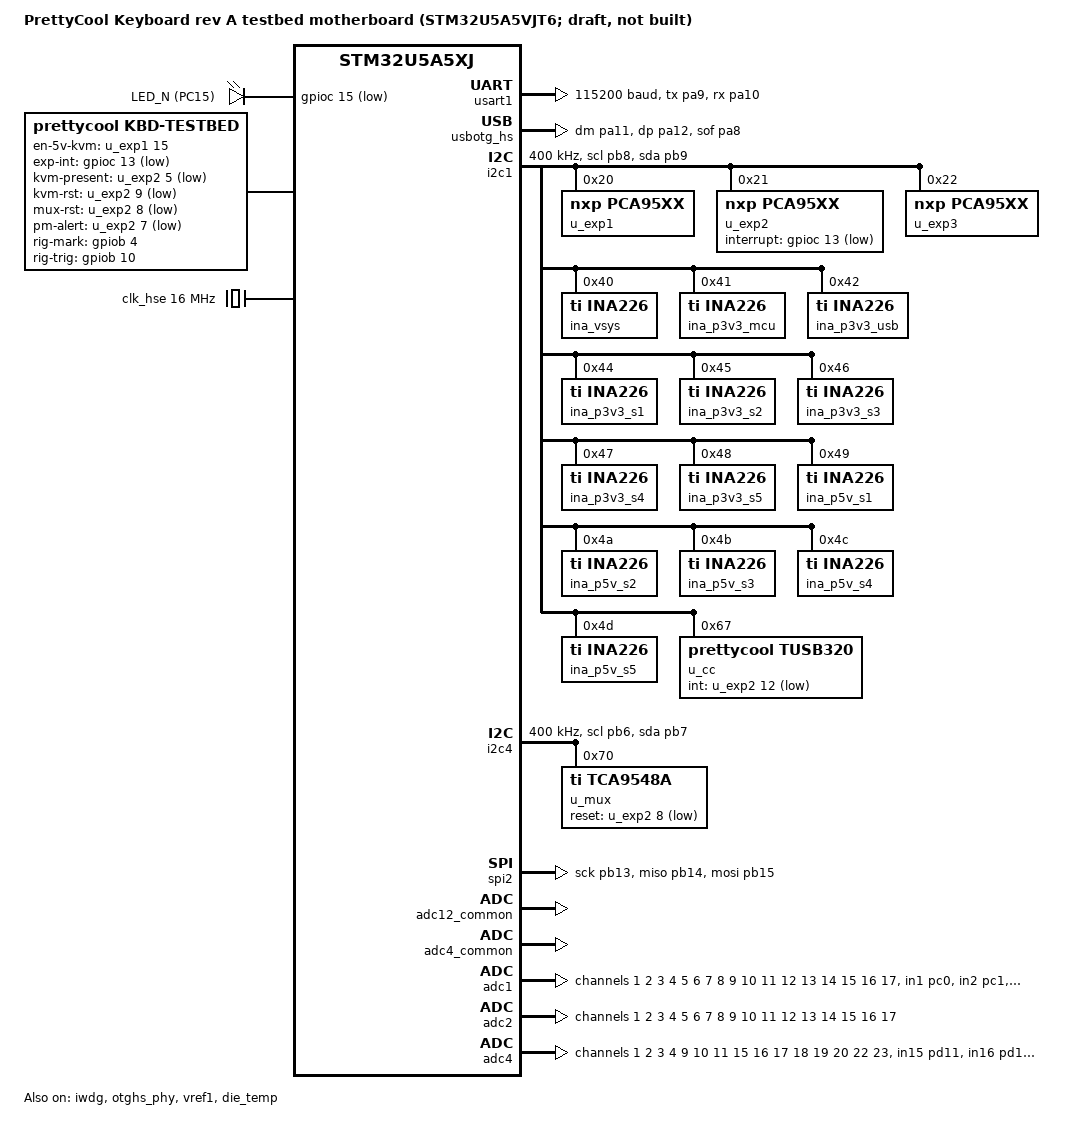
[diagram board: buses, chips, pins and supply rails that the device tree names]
/*
 * GENERATED by keyboard/firmware/boards/gen_board.py from keyboard/hardware/design/nets.py
 * and the SPEC constants in that script. Do not edit: change nets.py (or the script), regenerate.
 * nets.py rev A-testbed 2026-11-27; map hash 10b5eaea9fcebc38.
 *
 * PrettyCool Keyboard rev A testbed motherboard (SPEC §2, §5, §8): schematic captured and gated against nets.py,
 * NOT BUILT. Nothing in this file has run on hardware. Pin map: nets.MCU_PINS / nets.MCU_FUNC; expanders:
 * nets.EXPANDERS; monitors: nets.INA226_RAILS and INA226_CURRENT_LSB_UA; clocks: SPEC §8.1.
 *
 * SPDX-License-Identifier: Apache-2.0
 */

/dts-v1/;
#include <st/u5/stm32u5a5Xj.dtsi>
#include <st/u5/stm32u5a5vjtx-pinctrl.dtsi>
#include <zephyr/dt-bindings/adc/adc.h>
#include <zephyr/dt-bindings/i2c/i2c.h>

/ {
	model = "PrettyCool Keyboard rev A testbed motherboard (STM32U5A5VJT6; draft, not built)";
	compatible = "prettycool,kbd-testbed-a";

	chosen {
		zephyr,console = &usart1;
		zephyr,shell-uart = &usart1;
		zephyr,sram = &sram0;
		zephyr,flash = &flash0;
		zephyr,code-partition = &slot0_partition;
	};

	aliases {
		led0 = &status_led;
		watchdog0 = &iwdg;
		volt-sensor0 = &vref1;
		die-temp0 = &die_temp;
	};

	leds {
		compatible = "gpio-leds";

		/* LED_N on PC15-OSC32_OUT: PC13-PC15 may sink but not source (SPEC §5.2), so it is active low. */
		status_led: led_n {
			gpios = <&gpioc 15 GPIO_ACTIVE_LOW>;
			label = "LED_N (PC15)";
		};
	};

	/* The motherboard's own signals (SPEC §3, §4.3, §7.3), for the board service and the bring-up app. */
	testbed: testbed {
		compatible = "prettycool,kbd-testbed";
		en-5v-kvm-gpios = <&u_exp1 15 GPIO_ACTIVE_HIGH>;
		exp-int-gpios = <&gpioc 13 GPIO_ACTIVE_LOW>;
		kvm-present-gpios = <&u_exp2 5 GPIO_ACTIVE_LOW>;
		kvm-rst-gpios = <&u_exp2 9 GPIO_ACTIVE_LOW>;
		mux-rst-gpios = <&u_exp2 8 GPIO_ACTIVE_LOW>;
		pm-alert-gpios = <&u_exp2 7 GPIO_ACTIVE_LOW>;
		rig-mark-gpios = <&gpiob 4 GPIO_ACTIVE_HIGH>;
		rig-trig-gpios = <&gpiob 10 GPIO_ACTIVE_HIGH>;
		s5-pg-gpios = <&u_exp2 11 GPIO_ACTIVE_HIGH>;
		slot-fault-gpios = <&u_exp2 6 GPIO_ACTIVE_LOW>;
		slot-sync-gpios = <&gpioa 15 GPIO_ACTIVE_HIGH>;
		usbc-int-gpios = <&u_exp2 12 GPIO_ACTIVE_LOW>;
		vsys-pg-gpios = <&u_exp2 10 GPIO_ACTIVE_HIGH>;
		ina226-vsys = <&ina_vsys>;
		ina226-mcu = <&ina_p3v3_mcu>;
		ina226-usb = <&ina_p3v3_usb>;
		typec = <&u_cc>;
		slot-mux = <&u_mux>;
		kvm-i2c = <&mux_ch5>;
		slot-ldo-milliamps = <300>;
		base-load-milliamps = <45>;
		vsys-budget-max-milliamps = <2800>;
		vsys-budget-unconfigured-milliamps = <100>;
		vsys-trip-milliamps = <2960 3330 3620>;
		kvm-trip-milliamps = <519 577 644>;
		kvm-rule-milliamps = <500>;
	};

	/* The five coupon slots (SPEC §4.2-§4.4). Lanes: io-channels = AN0..AN3 on their primary converter;
	 * alt-adc-channels = <lane adc channel> for every other converter that reaches the lane's pin. */
	slots {
		slot1: slot-1 {
			compatible = "prettycool,coupon-slot";
			slot = <1>;
			io-channels = <&adc1 1>, <&adc1 2>, <&adc1 3>, <&adc1 4>;
			io-channel-names = "AN0", "AN1", "AN2", "AN3";
			alt-adc-channels = <0 2 1  0 4 1  1 2 2  1 4 2  2 2 3  2 4 3  3 2 4  3 4 4>;
			g-gpios = <&gpioe 2 GPIO_ACTIVE_HIGH>, <&gpioe 3 GPIO_ACTIVE_HIGH>, <&gpioe 4 GPIO_ACTIVE_HIGH>, <&gpioe 5 GPIO_ACTIVE_HIGH>, <&u_exp3 0 GPIO_ACTIVE_HIGH>, <&u_exp3 1 GPIO_ACTIVE_HIGH>;
			cs-gpios = <&gpioe 6 GPIO_ACTIVE_LOW>, <&gpioe 1 GPIO_ACTIVE_LOW>;
			irq-gpios = <&gpioc 14 GPIO_ACTIVE_LOW>;
			present-gpios = <&u_exp2 0 GPIO_ACTIVE_LOW>;
			en-3v3-gpios = <&u_exp1 0 GPIO_ACTIVE_HIGH>;
			en-5v-gpios = <&u_exp1 5 GPIO_ACTIVE_HIGH>;
			busen-gpios = <&u_exp1 10 GPIO_ACTIVE_LOW>;
			led-gpios = <&u_exp3 8 GPIO_ACTIVE_LOW>;
			ina226-3v3 = <&ina_p3v3_s1>;
			ina226-5v = <&ina_p5v_s1>;
			i2c-channel = <&mux_ch0>;
			rule-3v3-milliamps = <250>;
			rule-5v-milliamps = <500>;
			trip-3v3-milliamps = <256 292 335>;
			trip-5v-milliamps = <519 577 644>;
			rail-3v3 = <0>;
			rail-5v = <5>;
		};

		slot2: slot-2 {
			compatible = "prettycool,coupon-slot";
			slot = <2>;
			io-channels = <&adc1 5>, <&adc1 6>, <&adc1 7>, <&adc1 8>;
			io-channel-names = "AN0", "AN1", "AN2", "AN3";
			alt-adc-channels = <0 2 5  1 2 6  2 2 7  3 2 8>;
			g-gpios = <&gpiod 8 GPIO_ACTIVE_HIGH>, <&gpiod 9 GPIO_ACTIVE_HIGH>, <&gpiod 10 GPIO_ACTIVE_HIGH>, <&gpiod 14 GPIO_ACTIVE_HIGH>, <&u_exp3 2 GPIO_ACTIVE_HIGH>, <&u_exp3 3 GPIO_ACTIVE_HIGH>;
			cs-gpios = <&gpiod 15 GPIO_ACTIVE_LOW>, <&gpiod 7 GPIO_ACTIVE_LOW>;
			irq-gpios = <&gpiod 6 GPIO_ACTIVE_LOW>;
			present-gpios = <&u_exp2 1 GPIO_ACTIVE_LOW>;
			en-3v3-gpios = <&u_exp1 1 GPIO_ACTIVE_HIGH>;
			en-5v-gpios = <&u_exp1 6 GPIO_ACTIVE_HIGH>;
			busen-gpios = <&u_exp1 11 GPIO_ACTIVE_LOW>;
			led-gpios = <&u_exp3 9 GPIO_ACTIVE_LOW>;
			ina226-3v3 = <&ina_p3v3_s2>;
			ina226-5v = <&ina_p5v_s2>;
			i2c-channel = <&mux_ch1>;
			rule-3v3-milliamps = <250>;
			rule-5v-milliamps = <500>;
			trip-3v3-milliamps = <256 292 335>;
			trip-5v-milliamps = <519 577 644>;
			rail-3v3 = <1>;
			rail-5v = <6>;
		};

		slot3: slot-3 {
			compatible = "prettycool,coupon-slot";
			slot = <3>;
			io-channels = <&adc1 9>, <&adc1 10>, <&adc1 11>, <&adc1 12>;
			io-channel-names = "AN0", "AN1", "AN2", "AN3";
			alt-adc-channels = <0 2 9  0 4 9  1 2 10  1 4 10  2 2 11  2 4 11  3 2 12  3 4 20>;
			g-gpios = <&gpiod 0 GPIO_ACTIVE_HIGH>, <&gpiod 1 GPIO_ACTIVE_HIGH>, <&gpiod 2 GPIO_ACTIVE_HIGH>, <&gpiod 3 GPIO_ACTIVE_HIGH>, <&u_exp3 4 GPIO_ACTIVE_HIGH>, <&u_exp3 5 GPIO_ACTIVE_HIGH>;
			cs-gpios = <&gpiod 4 GPIO_ACTIVE_LOW>, <&gpiod 5 GPIO_ACTIVE_LOW>;
			irq-gpios = <&gpioe 0 GPIO_ACTIVE_LOW>;
			present-gpios = <&u_exp2 2 GPIO_ACTIVE_LOW>;
			en-3v3-gpios = <&u_exp1 2 GPIO_ACTIVE_HIGH>;
			en-5v-gpios = <&u_exp1 7 GPIO_ACTIVE_HIGH>;
			busen-gpios = <&u_exp1 12 GPIO_ACTIVE_LOW>;
			led-gpios = <&u_exp3 10 GPIO_ACTIVE_LOW>;
			ina226-3v3 = <&ina_p3v3_s3>;
			ina226-5v = <&ina_p5v_s3>;
			i2c-channel = <&mux_ch2>;
			rule-3v3-milliamps = <250>;
			rule-5v-milliamps = <500>;
			trip-3v3-milliamps = <256 292 335>;
			trip-5v-milliamps = <519 577 644>;
			rail-3v3 = <2>;
			rail-5v = <7>;
		};

		slot4: slot-4 {
			compatible = "prettycool,coupon-slot";
			slot = <4>;
			io-channels = <&adc1 13>, <&adc1 14>, <&adc1 15>, <&adc1 16>;
			io-channel-names = "AN0", "AN1", "AN2", "AN3";
			alt-adc-channels = <0 2 13  0 4 22  1 2 14  1 4 23  2 2 15  2 4 18  3 2 16  3 4 19>;
			g-gpios = <&gpioc 6 GPIO_ACTIVE_HIGH>, <&gpioc 7 GPIO_ACTIVE_HIGH>, <&gpioc 8 GPIO_ACTIVE_HIGH>, <&gpioc 9 GPIO_ACTIVE_HIGH>, <&u_exp3 6 GPIO_ACTIVE_HIGH>, <&u_exp3 7 GPIO_ACTIVE_HIGH>;
			cs-gpios = <&gpiob 12 GPIO_ACTIVE_LOW>, <&gpioc 12 GPIO_ACTIVE_LOW>;
			irq-gpios = <&gpiob 5 GPIO_ACTIVE_LOW>;
			present-gpios = <&u_exp2 3 GPIO_ACTIVE_LOW>;
			en-3v3-gpios = <&u_exp1 3 GPIO_ACTIVE_HIGH>;
			en-5v-gpios = <&u_exp1 8 GPIO_ACTIVE_HIGH>;
			busen-gpios = <&u_exp1 13 GPIO_ACTIVE_LOW>;
			led-gpios = <&u_exp3 11 GPIO_ACTIVE_LOW>;
			ina226-3v3 = <&ina_p3v3_s4>;
			ina226-5v = <&ina_p5v_s4>;
			i2c-channel = <&mux_ch3>;
			rule-3v3-milliamps = <250>;
			rule-5v-milliamps = <500>;
			trip-3v3-milliamps = <256 292 335>;
			trip-5v-milliamps = <519 577 644>;
			rail-3v3 = <3>;
			rail-5v = <8>;
		};

		slot5: slot-5 {
			compatible = "prettycool,coupon-slot";
			slot = <5>;
			io-channels = <&adc1 17>, <&adc4 15>, <&adc4 16>, <&adc4 17>;
			io-channel-names = "AN0", "AN1", "AN2", "AN3";
			alt-adc-channels = <0 2 17>;
			g-gpios = <&gpioe 9 GPIO_ACTIVE_HIGH>, <&gpioe 11 GPIO_ACTIVE_HIGH>, <&gpioe 13 GPIO_ACTIVE_HIGH>, <&gpioe 8 GPIO_ACTIVE_HIGH>, <&gpioe 10 GPIO_ACTIVE_HIGH>, <&gpioe 12 GPIO_ACTIVE_HIGH>;
			cs-gpios = <&gpioe 14 GPIO_ACTIVE_LOW>, <&gpioe 7 GPIO_ACTIVE_LOW>;
			irq-gpios = <&gpioe 15 GPIO_ACTIVE_LOW>;
			/* TIM1_BKIN: never gpio_pin_configure() it while TIM1 runs (SPEC §5.3). */
			irq-is-tim1-bkin;
			present-gpios = <&u_exp2 4 GPIO_ACTIVE_LOW>;
			en-3v3-gpios = <&u_exp1 4 GPIO_ACTIVE_HIGH>;
			en-5v-gpios = <&u_exp1 9 GPIO_ACTIVE_HIGH>;
			busen-gpios = <&u_exp1 14 GPIO_ACTIVE_LOW>;
			led-gpios = <&u_exp3 12 GPIO_ACTIVE_LOW>;
			pg-5v-gpios = <&u_exp2 11 GPIO_ACTIVE_HIGH>;
			ina226-3v3 = <&ina_p3v3_s5>;
			ina226-5v = <&ina_p5v_s5>;
			i2c-channel = <&mux_ch4>;
			rule-3v3-milliamps = <250>;
			rule-5v-milliamps = <2000>;
			trip-3v3-milliamps = <256 292 335>;
			trip-5v-milliamps = <2010 2270 2460>;
			rail-3v3 = <4>;
			rail-5v = <9>;
		};
	};
};

/* Clocks, SPEC §8.1: HSE 16 MHz crystal (no bypass), PLL1 M 4 N 80 Q 2 R 2 = 160 MHz, as the Nucleo. */
&clk_hse {
	clock-frequency = <DT_FREQ_M(16)>;
	status = "okay";
};

/* HSI48 as on the Nucleo (RNG, CK48); the HS PHY takes the HSE (OTGHS_SEL = 0, stm32u5_usbotg_hs.dtsi). */
&clk_hsi48 {
	status = "okay";
};

/*
 * &clk_lse stays disabled (the SoC default): no LSE crystal on rev A, PC14 is S1_IRQ_N and PC15 is LED_N
 * (SPEC §5.2), and with no crystal the clock driver waits for LSERDY forever (SPEC §8.1). If an RTC is ever
 * enabled, clock it from the LSI.
 */

&pll1 {
	div-m = <4>;
	mul-n = <80>;
	div-q = <2>;
	div-r = <2>;
	clocks = <&clk_hse>;
	status = "okay";
};

&rcc {
	clocks = <&pll1>;
	clock-frequency = <DT_FREQ_M(160)>;
	ahb-prescaler = <1>;
	apb1-prescaler = <1>;
	apb2-prescaler = <1>;
	apb3-prescaler = <1>;
};

&flash0 {
	partitions {
		#address-cells = <1>;
		#size-cells = <1>;
		ranges;

		/* As the Nucleo's layout (TZEN = 0). The bring-up app links at 0x08000000 (no MCUboot). */
		boot_partition: partition@0 {
			compatible = "zephyr,mapped-partition";
			label = "mcuboot";
			reg = <0x00000000 DT_SIZE_K(64)>;
		};

		slot0_partition: partition@10000 {
			compatible = "zephyr,mapped-partition";
			label = "image-0";
			reg = <0x00010000 DT_SIZE_K(1952)>;
		};

		slot1_partition: partition@1f8000 {
			compatible = "zephyr,mapped-partition";
			label = "image-1";
			reg = <0x001f8000 DT_SIZE_K(1960)>;
		};

		storage_partition: partition@3e2000 {
			compatible = "zephyr,mapped-partition";
			label = "storage";
			reg = <0x003e2000 DT_SIZE_K(120)>;
		};
	};
};

/* Console: USART1 on PA9/PA10, the J_SWD STDC14's VCP pins (SPEC §7.2, §8.3). */
&usart1 {
	pinctrl-0 = <&usart1_tx_pa9 &usart1_rx_pa10>;
	pinctrl-names = "default";
	current-speed = <115200>;
	status = "okay";
};

/*
 * KVM link (SPEC §7.4), disabled: an enabled UART idles its TX high, which would back-power an unpowered KVM
 * coupon through its RX pin (the slot power rule of SPEC §3.5 applied to J_KVM). Enable it only while
 * +5V_KVM is on.
 */
&uart4 {
	pinctrl-0 = <&uart4_tx_pc10 &uart4_rx_pc11>;
	pinctrl-names = "default";
	current-speed = <115200>;
	status = "disabled";
};

&gpdma1 {
	status = "okay";
};

&iwdg {
	status = "okay";
};

/* USB high speed on the embedded PHY (SPEC §7.1, §8.2). USB_SOF (PA8) to J_RIG; the OTG core drives it only
 * once its SOF output is enabled, which Zephyr v4.5.0 does not do. */
zephyr_udc0: &usbotg_hs {
	pinctrl-0 = <&usb_otg_hs_dm_pa11 &usb_otg_hs_dp_pa12 &usb_otg_hs_sof_pa8>;
	pinctrl-names = "default";
	status = "okay";
};

&otghs_phy {
	status = "okay";
};

/* I2C1, 400 kHz, 2.2 k pull-ups to +3V3: the 13 INA226s, the three TCA9535s and U_CC (SPEC §3.4). */
&i2c1 {
	pinctrl-0 = <&i2c1_scl_pb8 &i2c1_sda_pb9>;
	pinctrl-names = "default";
	/* bus recovery (SPEC §5.2: a warm reset mid-read can leave a target holding SDA low): open drain, or the
	 * recovery would drive SDA push-pull against it (i2c_stm32_common.c configures GPIO_OUTPUT_HIGH) */
	scl-gpios = <&gpiob 8 (GPIO_ACTIVE_HIGH | GPIO_OPEN_DRAIN)>;
	sda-gpios = <&gpiob 9 (GPIO_ACTIVE_HIGH | GPIO_OPEN_DRAIN)>;
	clock-frequency = <I2C_BITRATE_FAST>;
	status = "okay";

	/* U_EXP1 TCA9535 (rail enables, bus-switch enables). Restored outputs 0xFFFF, output register 0x7C00, configuration
	 * 0x0000. nxp,pca95xx with neither has-pud nor has-interrupt-mask-reg (SPEC §8.4). */
	u_exp1: gpio@20 {
		compatible = "nxp,pca95xx";
		reg = <0x20>;
		gpio-controller;
		#gpio-cells = <2>;
		ngpios = <16>;
	};

	/* U_EXP2 TCA9535 (PRESENT_N, faults, alerts, mux and KVM resets, the USB-C detect interrupt). Restored outputs 0x0300, output register 0xFDFF, configuration
	 * 0xFCFF. nxp,pca95xx with neither has-pud nor has-interrupt-mask-reg (SPEC §8.4). */
	u_exp2: gpio@21 {
		compatible = "nxp,pca95xx";
		reg = <0x21>;
		gpio-controller;
		#gpio-cells = <2>;
		ngpios = <16>;
		interrupt-gpios = <&gpioc 13 GPIO_ACTIVE_LOW>;
	};

	/* U_EXP3 TCA9535 (S1-S4 G4/G5, slot LEDs). Restored outputs 0x1FFF, output register 0xFF00, configuration
	 * 0xE000. nxp,pca95xx with neither has-pud nor has-interrupt-mask-reg (SPEC §8.4). */
	u_exp3: gpio@22 {
		compatible = "nxp,pca95xx";
		reg = <0x22>;
		gpio-controller;
		#gpio-cells = <2>;
		ngpios = <16>;
	};

	/* VSYS: 0.02 ohm shunt, current LSB 125 uA (CAL 2048), full scale 4096 mA. */
	ina_vsys: ina226@40 {
		compatible = "ti,ina226";
		reg = <0x40>;
		current-lsb-microamps = <125>;
		rshunt-micro-ohms = <20000>;
	};

	/* +3V3_MCU: 0.5 ohm shunt, current LSB 5 uA (CAL 2048), full scale 164 mA. */
	ina_p3v3_mcu: ina226@41 {
		compatible = "ti,ina226";
		reg = <0x41>;
		current-lsb-microamps = <5>;
		rshunt-micro-ohms = <500000>;
	};

	/* +3V3_USB: 1 ohm shunt, current LSB 3 uA (CAL 1707), full scale 82 mA. */
	ina_p3v3_usb: ina226@42 {
		compatible = "ti,ina226";
		reg = <0x42>;
		current-lsb-microamps = <3>;
		rshunt-micro-ohms = <1000000>;
	};

	/* +3V3_S1: 0.24 ohm shunt, current LSB 11 uA (CAL 1939), full scale 341 mA. */
	ina_p3v3_s1: ina226@44 {
		compatible = "ti,ina226";
		reg = <0x44>;
		current-lsb-microamps = <11>;
		rshunt-micro-ohms = <240000>;
	};

	/* +3V3_S2: 0.24 ohm shunt, current LSB 11 uA (CAL 1939), full scale 341 mA. */
	ina_p3v3_s2: ina226@45 {
		compatible = "ti,ina226";
		reg = <0x45>;
		current-lsb-microamps = <11>;
		rshunt-micro-ohms = <240000>;
	};

	/* +3V3_S3: 0.24 ohm shunt, current LSB 11 uA (CAL 1939), full scale 341 mA. */
	ina_p3v3_s3: ina226@46 {
		compatible = "ti,ina226";
		reg = <0x46>;
		current-lsb-microamps = <11>;
		rshunt-micro-ohms = <240000>;
	};

	/* +3V3_S4: 0.24 ohm shunt, current LSB 11 uA (CAL 1939), full scale 341 mA. */
	ina_p3v3_s4: ina226@47 {
		compatible = "ti,ina226";
		reg = <0x47>;
		current-lsb-microamps = <11>;
		rshunt-micro-ohms = <240000>;
	};

	/* +3V3_S5: 0.24 ohm shunt, current LSB 11 uA (CAL 1939), full scale 341 mA. */
	ina_p3v3_s5: ina226@48 {
		compatible = "ti,ina226";
		reg = <0x48>;
		current-lsb-microamps = <11>;
		rshunt-micro-ohms = <240000>;
	};

	/* +5V_S1: 0.1 ohm shunt, current LSB 25 uA (CAL 2048), full scale 819 mA. */
	ina_p5v_s1: ina226@49 {
		compatible = "ti,ina226";
		reg = <0x49>;
		current-lsb-microamps = <25>;
		rshunt-micro-ohms = <100000>;
	};

	/* +5V_S2: 0.1 ohm shunt, current LSB 25 uA (CAL 2048), full scale 819 mA. */
	ina_p5v_s2: ina226@4a {
		compatible = "ti,ina226";
		reg = <0x4a>;
		current-lsb-microamps = <25>;
		rshunt-micro-ohms = <100000>;
	};

	/* +5V_S3: 0.1 ohm shunt, current LSB 25 uA (CAL 2048), full scale 819 mA. */
	ina_p5v_s3: ina226@4b {
		compatible = "ti,ina226";
		reg = <0x4b>;
		current-lsb-microamps = <25>;
		rshunt-micro-ohms = <100000>;
	};

	/* +5V_S4: 0.1 ohm shunt, current LSB 25 uA (CAL 2048), full scale 819 mA. */
	ina_p5v_s4: ina226@4c {
		compatible = "ti,ina226";
		reg = <0x4c>;
		current-lsb-microamps = <25>;
		rshunt-micro-ohms = <100000>;
	};

	/* +5V_S5: 0.02 ohm shunt, current LSB 125 uA (CAL 2048), full scale 4096 mA. */
	ina_p5v_s5: ina226@4d {
		compatible = "ti,ina226";
		reg = <0x4d>;
		current-lsb-microamps = <125>;
		rshunt-micro-ohms = <20000>;
	};

	/* U_CC TUSB320LAIRWBR: Type-C source advertisement, read only (SPEC §3.8, §8.4). Its INT_N reaches
	 * the MCU through U_EXP2 (no MCU pin). Zephyr v4.5.0 has no driver for it. */
	u_cc: typec@67 {
		compatible = "prettycool,tusb320";
		reg = <0x67>;
		int-gpios = <&u_exp2 12 GPIO_ACTIVE_LOW>;
		i2c-ready-ms = <100>;
		decide-ms = <200>;
	};
};

/* I2C4, 400 kHz, 2.2 k pull-ups to +3V3, to the slot mux only (SPEC §4.5). */
&i2c4 {
	pinctrl-0 = <&i2c4_scl_pb6 &i2c4_sda_pb7>;
	pinctrl-names = "default";
	/* bus recovery (SPEC §5.2: a warm reset mid-read can leave a target holding SDA low): open drain, or the
	 * recovery would drive SDA push-pull against it (i2c_stm32_common.c configures GPIO_OUTPUT_HIGH) */
	scl-gpios = <&gpiob 6 (GPIO_ACTIVE_HIGH | GPIO_OPEN_DRAIN)>;
	sda-gpios = <&gpiob 7 (GPIO_ACTIVE_HIGH | GPIO_OPEN_DRAIN)>;
	clock-frequency = <I2C_BITRATE_FAST>;
	status = "okay";

	/* U_MUX TCA9548A: ch0-ch4 = S1-S5, ch5 = KVM, ch6/ch7 = test pads. The driver never pulses RESET (it only deasserts it) and starts
	 * its channel cache at 0 without writing the device: after a warm reset the board service deselects
	 * the mux itself (SPEC §3.5, §8.4). idle-disconnect: no channel stays selected between transfers. */
	u_mux: mux@70 {
		compatible = "ti,tca9548a";
		reg = <0x70>;
		#address-cells = <1>;
		#size-cells = <0>;
		reset-gpios = <&u_exp2 8 GPIO_ACTIVE_LOW>;
		i2c-mux-idle-disconnect;

		/* channel 0: S1 */
		mux_ch0: i2c@0 {
			reg = <0>;
			#address-cells = <1>;
			#size-cells = <0>;
		};

		/* channel 1: S2 */
		mux_ch1: i2c@1 {
			reg = <1>;
			#address-cells = <1>;
			#size-cells = <0>;
		};

		/* channel 2: S3 */
		mux_ch2: i2c@2 {
			reg = <2>;
			#address-cells = <1>;
			#size-cells = <0>;
		};

		/* channel 3: S4 */
		mux_ch3: i2c@3 {
			reg = <3>;
			#address-cells = <1>;
			#size-cells = <0>;
		};

		/* channel 4: S5 */
		mux_ch4: i2c@4 {
			reg = <4>;
			#address-cells = <1>;
			#size-cells = <0>;
		};

		/* channel 5: J_KVM */
		mux_ch5: i2c@5 {
			reg = <5>;
			#address-cells = <1>;
			#size-cells = <0>;
		};

		/* channel 6: test pads (U_CC's fallback home, SPEC §3.4) */
		mux_ch6: i2c@6 {
			reg = <6>;
			#address-cells = <1>;
			#size-cells = <0>;
		};

		/* channel 7: test pads */
		mux_ch7: i2c@7 {
			reg = <7>;
			#address-cells = <1>;
			#size-cells = <0>;
		};
	};
};

/*
 * SPI2, shared by the slots through their bus switches (SPEC §4.3). No cs-gpios here: the SPI driver would
 * drive every listed CS high at init, into unpowered coupons (the CS lines go straight to the slots, SPEC
 * §3.5). Each slot node lists its own two CS lines; the application drives them.
 */
&spi2 {
	pinctrl-0 = <&spi2_sck_pb13 &spi2_miso_pb14 &spi2_mosi_pb15>;
	pinctrl-names = "default";
	status = "okay";
};

/*
 * Timers, disabled: their pins are slot lines, and an application that uses them enables both nodes in an
 * overlay. TIM2 is the frame timer (CH1 SLOT_SYNC out, CH3 RIG_TRIG capture; SPEC §6.1), TIM1 drives S5's
 * DRV8316 with its break input on S5_IRQ_N (SPEC §5.3), TIM8 sits behind S4's G0-G3.
 */
&timers2 {
	st,prescaler = <0>;
	status = "disabled";

	pwm2: pwm {
		pinctrl-0 = <&tim2_ch1_pa15 &tim2_ch3_pb10>;
		pinctrl-names = "default";
		status = "disabled";
	};
};

&timers1 {
	st,prescaler = <0>;
	status = "disabled";

	pwm1: pwm {
		pinctrl-0 = <&tim1_ch1_pe9 &tim1_ch2_pe11 &tim1_ch3_pe13 &tim1_ch1n_pe8 &tim1_ch2n_pe10 &tim1_ch3n_pe12 &tim1_bkin_pe15>;
		pinctrl-names = "default";
		status = "disabled";
	};
};

&timers8 {
	st,prescaler = <0>;
	status = "disabled";

	pwm8: pwm {
		pinctrl-0 = <&tim8_ch1_pc6 &tim8_ch2_pc7 &tim8_ch3_pc8 &tim8_ch4_pc9>;
		pinctrl-names = "default";
		status = "disabled";
	};
};

/* ADCs, SPEC §4.4, §6.2: kernel clock HCLK / 4 = 40 MHz; VREF+ = VDDA = +3V3A. Every lane is a channel on every
 * converter that reaches its pin (nets.LANE_ADC). Acquisition 391 cycles (ADC1/2) and 815 (ADC4, 814.5): slow
 * enough for any lane source of SPEC §4.9; the scan engine sets its own. */
&adc12_common {
	st,adc-prescaler = <4>;
	vref-mv = <3300>;
	st,adc-clock-source = "ASYNC";
	status = "okay";
};

&adc4_common {
	st,adc-prescaler = <4>;
	vref-mv = <3300>;
	st,adc-clock-source = "ASYNC";
	status = "okay";
};

&adc1 {
	pinctrl-0 = <&adc1_in1_pc0 &adc1_in2_pc1 &adc1_in3_pc2 &adc1_in4_pc3 &adc1_in5_pa0 &adc1_in6_pa1 &adc1_in7_pa2 &adc1_in8_pa3 &adc1_in9_pa4 &adc1_in10_pa5 &adc1_in11_pa6 &adc1_in12_pa7 &adc1_in13_pc4 &adc1_in14_pc5 &adc1_in15_pb0 &adc1_in16_pb1 &adc1_in17_pb2>;
	pinctrl-names = "default";
	#address-cells = <1>;
	#size-cells = <0>;
	status = "okay";

	channel@1 {  /* PC0 S1_AN0_ADC */
		reg = <1>;
		zephyr,gain = "ADC_GAIN_1";
		zephyr,reference = "ADC_REF_INTERNAL";
		zephyr,acquisition-time = <ADC_ACQ_TIME(ADC_ACQ_TIME_TICKS, 391)>;
		zephyr,resolution = <14>;
	};

	channel@2 {  /* PC1 S1_AN1_ADC */
		reg = <2>;
		zephyr,gain = "ADC_GAIN_1";
		zephyr,reference = "ADC_REF_INTERNAL";
		zephyr,acquisition-time = <ADC_ACQ_TIME(ADC_ACQ_TIME_TICKS, 391)>;
		zephyr,resolution = <14>;
	};

	channel@3 {  /* PC2 S1_AN2_ADC */
		reg = <3>;
		zephyr,gain = "ADC_GAIN_1";
		zephyr,reference = "ADC_REF_INTERNAL";
		zephyr,acquisition-time = <ADC_ACQ_TIME(ADC_ACQ_TIME_TICKS, 391)>;
		zephyr,resolution = <14>;
	};

	channel@4 {  /* PC3 S1_AN3_ADC */
		reg = <4>;
		zephyr,gain = "ADC_GAIN_1";
		zephyr,reference = "ADC_REF_INTERNAL";
		zephyr,acquisition-time = <ADC_ACQ_TIME(ADC_ACQ_TIME_TICKS, 391)>;
		zephyr,resolution = <14>;
	};

	channel@5 {  /* PA0 S2_AN0_ADC */
		reg = <5>;
		zephyr,gain = "ADC_GAIN_1";
		zephyr,reference = "ADC_REF_INTERNAL";
		zephyr,acquisition-time = <ADC_ACQ_TIME(ADC_ACQ_TIME_TICKS, 391)>;
		zephyr,resolution = <14>;
	};

	channel@6 {  /* PA1 S2_AN1_ADC */
		reg = <6>;
		zephyr,gain = "ADC_GAIN_1";
		zephyr,reference = "ADC_REF_INTERNAL";
		zephyr,acquisition-time = <ADC_ACQ_TIME(ADC_ACQ_TIME_TICKS, 391)>;
		zephyr,resolution = <14>;
	};

	channel@7 {  /* PA2 S2_AN2_ADC */
		reg = <7>;
		zephyr,gain = "ADC_GAIN_1";
		zephyr,reference = "ADC_REF_INTERNAL";
		zephyr,acquisition-time = <ADC_ACQ_TIME(ADC_ACQ_TIME_TICKS, 391)>;
		zephyr,resolution = <14>;
	};

	channel@8 {  /* PA3 S2_AN3_ADC */
		reg = <8>;
		zephyr,gain = "ADC_GAIN_1";
		zephyr,reference = "ADC_REF_INTERNAL";
		zephyr,acquisition-time = <ADC_ACQ_TIME(ADC_ACQ_TIME_TICKS, 391)>;
		zephyr,resolution = <14>;
	};

	channel@9 {  /* PA4 S3_AN0_ADC */
		reg = <9>;
		zephyr,gain = "ADC_GAIN_1";
		zephyr,reference = "ADC_REF_INTERNAL";
		zephyr,acquisition-time = <ADC_ACQ_TIME(ADC_ACQ_TIME_TICKS, 391)>;
		zephyr,resolution = <14>;
	};

	channel@a {  /* PA5 S3_AN1_ADC */
		reg = <10>;
		zephyr,gain = "ADC_GAIN_1";
		zephyr,reference = "ADC_REF_INTERNAL";
		zephyr,acquisition-time = <ADC_ACQ_TIME(ADC_ACQ_TIME_TICKS, 391)>;
		zephyr,resolution = <14>;
	};

	channel@b {  /* PA6 S3_AN2_ADC */
		reg = <11>;
		zephyr,gain = "ADC_GAIN_1";
		zephyr,reference = "ADC_REF_INTERNAL";
		zephyr,acquisition-time = <ADC_ACQ_TIME(ADC_ACQ_TIME_TICKS, 391)>;
		zephyr,resolution = <14>;
	};

	channel@c {  /* PA7 S3_AN3_ADC */
		reg = <12>;
		zephyr,gain = "ADC_GAIN_1";
		zephyr,reference = "ADC_REF_INTERNAL";
		zephyr,acquisition-time = <ADC_ACQ_TIME(ADC_ACQ_TIME_TICKS, 391)>;
		zephyr,resolution = <14>;
	};

	channel@d {  /* PC4 S4_AN0_ADC */
		reg = <13>;
		zephyr,gain = "ADC_GAIN_1";
		zephyr,reference = "ADC_REF_INTERNAL";
		zephyr,acquisition-time = <ADC_ACQ_TIME(ADC_ACQ_TIME_TICKS, 391)>;
		zephyr,resolution = <14>;
	};

	channel@e {  /* PC5 S4_AN1_ADC */
		reg = <14>;
		zephyr,gain = "ADC_GAIN_1";
		zephyr,reference = "ADC_REF_INTERNAL";
		zephyr,acquisition-time = <ADC_ACQ_TIME(ADC_ACQ_TIME_TICKS, 391)>;
		zephyr,resolution = <14>;
	};

	channel@f {  /* PB0 S4_AN2_ADC */
		reg = <15>;
		zephyr,gain = "ADC_GAIN_1";
		zephyr,reference = "ADC_REF_INTERNAL";
		zephyr,acquisition-time = <ADC_ACQ_TIME(ADC_ACQ_TIME_TICKS, 391)>;
		zephyr,resolution = <14>;
	};

	channel@10 {  /* PB1 S4_AN3_ADC */
		reg = <16>;
		zephyr,gain = "ADC_GAIN_1";
		zephyr,reference = "ADC_REF_INTERNAL";
		zephyr,acquisition-time = <ADC_ACQ_TIME(ADC_ACQ_TIME_TICKS, 391)>;
		zephyr,resolution = <14>;
	};

	channel@11 {  /* PB2 S5_AN0_ADC */
		reg = <17>;
		zephyr,gain = "ADC_GAIN_1";
		zephyr,reference = "ADC_REF_INTERNAL";
		zephyr,acquisition-time = <ADC_ACQ_TIME(ADC_ACQ_TIME_TICKS, 391)>;
		zephyr,resolution = <14>;
	};
};

&adc2 {
	/* Same pins as ADC1, whose pinctrl puts them in analog mode. */
	#address-cells = <1>;
	#size-cells = <0>;
	status = "okay";

	channel@1 {  /* PC0 S1_AN0_ADC */
		reg = <1>;
		zephyr,gain = "ADC_GAIN_1";
		zephyr,reference = "ADC_REF_INTERNAL";
		zephyr,acquisition-time = <ADC_ACQ_TIME(ADC_ACQ_TIME_TICKS, 391)>;
		zephyr,resolution = <14>;
	};

	channel@2 {  /* PC1 S1_AN1_ADC */
		reg = <2>;
		zephyr,gain = "ADC_GAIN_1";
		zephyr,reference = "ADC_REF_INTERNAL";
		zephyr,acquisition-time = <ADC_ACQ_TIME(ADC_ACQ_TIME_TICKS, 391)>;
		zephyr,resolution = <14>;
	};

	channel@3 {  /* PC2 S1_AN2_ADC */
		reg = <3>;
		zephyr,gain = "ADC_GAIN_1";
		zephyr,reference = "ADC_REF_INTERNAL";
		zephyr,acquisition-time = <ADC_ACQ_TIME(ADC_ACQ_TIME_TICKS, 391)>;
		zephyr,resolution = <14>;
	};

	channel@4 {  /* PC3 S1_AN3_ADC */
		reg = <4>;
		zephyr,gain = "ADC_GAIN_1";
		zephyr,reference = "ADC_REF_INTERNAL";
		zephyr,acquisition-time = <ADC_ACQ_TIME(ADC_ACQ_TIME_TICKS, 391)>;
		zephyr,resolution = <14>;
	};

	channel@5 {  /* PA0 S2_AN0_ADC */
		reg = <5>;
		zephyr,gain = "ADC_GAIN_1";
		zephyr,reference = "ADC_REF_INTERNAL";
		zephyr,acquisition-time = <ADC_ACQ_TIME(ADC_ACQ_TIME_TICKS, 391)>;
		zephyr,resolution = <14>;
	};

	channel@6 {  /* PA1 S2_AN1_ADC */
		reg = <6>;
		zephyr,gain = "ADC_GAIN_1";
		zephyr,reference = "ADC_REF_INTERNAL";
		zephyr,acquisition-time = <ADC_ACQ_TIME(ADC_ACQ_TIME_TICKS, 391)>;
		zephyr,resolution = <14>;
	};

	channel@7 {  /* PA2 S2_AN2_ADC */
		reg = <7>;
		zephyr,gain = "ADC_GAIN_1";
		zephyr,reference = "ADC_REF_INTERNAL";
		zephyr,acquisition-time = <ADC_ACQ_TIME(ADC_ACQ_TIME_TICKS, 391)>;
		zephyr,resolution = <14>;
	};

	channel@8 {  /* PA3 S2_AN3_ADC */
		reg = <8>;
		zephyr,gain = "ADC_GAIN_1";
		zephyr,reference = "ADC_REF_INTERNAL";
		zephyr,acquisition-time = <ADC_ACQ_TIME(ADC_ACQ_TIME_TICKS, 391)>;
		zephyr,resolution = <14>;
	};

	channel@9 {  /* PA4 S3_AN0_ADC */
		reg = <9>;
		zephyr,gain = "ADC_GAIN_1";
		zephyr,reference = "ADC_REF_INTERNAL";
		zephyr,acquisition-time = <ADC_ACQ_TIME(ADC_ACQ_TIME_TICKS, 391)>;
		zephyr,resolution = <14>;
	};

	channel@a {  /* PA5 S3_AN1_ADC */
		reg = <10>;
		zephyr,gain = "ADC_GAIN_1";
		zephyr,reference = "ADC_REF_INTERNAL";
		zephyr,acquisition-time = <ADC_ACQ_TIME(ADC_ACQ_TIME_TICKS, 391)>;
		zephyr,resolution = <14>;
	};

	channel@b {  /* PA6 S3_AN2_ADC */
		reg = <11>;
		zephyr,gain = "ADC_GAIN_1";
		zephyr,reference = "ADC_REF_INTERNAL";
		zephyr,acquisition-time = <ADC_ACQ_TIME(ADC_ACQ_TIME_TICKS, 391)>;
		zephyr,resolution = <14>;
	};

	channel@c {  /* PA7 S3_AN3_ADC */
		reg = <12>;
		zephyr,gain = "ADC_GAIN_1";
		zephyr,reference = "ADC_REF_INTERNAL";
		zephyr,acquisition-time = <ADC_ACQ_TIME(ADC_ACQ_TIME_TICKS, 391)>;
		zephyr,resolution = <14>;
	};

	channel@d {  /* PC4 S4_AN0_ADC */
		reg = <13>;
		zephyr,gain = "ADC_GAIN_1";
		zephyr,reference = "ADC_REF_INTERNAL";
		zephyr,acquisition-time = <ADC_ACQ_TIME(ADC_ACQ_TIME_TICKS, 391)>;
		zephyr,resolution = <14>;
	};

	channel@e {  /* PC5 S4_AN1_ADC */
		reg = <14>;
		zephyr,gain = "ADC_GAIN_1";
		zephyr,reference = "ADC_REF_INTERNAL";
		zephyr,acquisition-time = <ADC_ACQ_TIME(ADC_ACQ_TIME_TICKS, 391)>;
		zephyr,resolution = <14>;
	};

	channel@f {  /* PB0 S4_AN2_ADC */
		reg = <15>;
		zephyr,gain = "ADC_GAIN_1";
		zephyr,reference = "ADC_REF_INTERNAL";
		zephyr,acquisition-time = <ADC_ACQ_TIME(ADC_ACQ_TIME_TICKS, 391)>;
		zephyr,resolution = <14>;
	};

	channel@10 {  /* PB1 S4_AN3_ADC */
		reg = <16>;
		zephyr,gain = "ADC_GAIN_1";
		zephyr,reference = "ADC_REF_INTERNAL";
		zephyr,acquisition-time = <ADC_ACQ_TIME(ADC_ACQ_TIME_TICKS, 391)>;
		zephyr,resolution = <14>;
	};

	channel@11 {  /* PB2 S5_AN0_ADC */
		reg = <17>;
		zephyr,gain = "ADC_GAIN_1";
		zephyr,reference = "ADC_REF_INTERNAL";
		zephyr,acquisition-time = <ADC_ACQ_TIME(ADC_ACQ_TIME_TICKS, 391)>;
		zephyr,resolution = <14>;
	};
};

&adc4 {
	pinctrl-0 = <&adc4_in15_pd11 &adc4_in16_pd12 &adc4_in17_pd13>;
	pinctrl-names = "default";
	#address-cells = <1>;
	#size-cells = <0>;
	status = "okay";

	channel@1 {  /* PC0 S1_AN0_ADC */
		reg = <1>;
		zephyr,gain = "ADC_GAIN_1";
		zephyr,reference = "ADC_REF_INTERNAL";
		zephyr,acquisition-time = <ADC_ACQ_TIME(ADC_ACQ_TIME_TICKS, 815)>;
		zephyr,resolution = <12>;
	};

	channel@2 {  /* PC1 S1_AN1_ADC */
		reg = <2>;
		zephyr,gain = "ADC_GAIN_1";
		zephyr,reference = "ADC_REF_INTERNAL";
		zephyr,acquisition-time = <ADC_ACQ_TIME(ADC_ACQ_TIME_TICKS, 815)>;
		zephyr,resolution = <12>;
	};

	channel@3 {  /* PC2 S1_AN2_ADC */
		reg = <3>;
		zephyr,gain = "ADC_GAIN_1";
		zephyr,reference = "ADC_REF_INTERNAL";
		zephyr,acquisition-time = <ADC_ACQ_TIME(ADC_ACQ_TIME_TICKS, 815)>;
		zephyr,resolution = <12>;
	};

	channel@4 {  /* PC3 S1_AN3_ADC */
		reg = <4>;
		zephyr,gain = "ADC_GAIN_1";
		zephyr,reference = "ADC_REF_INTERNAL";
		zephyr,acquisition-time = <ADC_ACQ_TIME(ADC_ACQ_TIME_TICKS, 815)>;
		zephyr,resolution = <12>;
	};

	channel@9 {  /* PA4 S3_AN0_ADC */
		reg = <9>;
		zephyr,gain = "ADC_GAIN_1";
		zephyr,reference = "ADC_REF_INTERNAL";
		zephyr,acquisition-time = <ADC_ACQ_TIME(ADC_ACQ_TIME_TICKS, 815)>;
		zephyr,resolution = <12>;
	};

	channel@a {  /* PA5 S3_AN1_ADC */
		reg = <10>;
		zephyr,gain = "ADC_GAIN_1";
		zephyr,reference = "ADC_REF_INTERNAL";
		zephyr,acquisition-time = <ADC_ACQ_TIME(ADC_ACQ_TIME_TICKS, 815)>;
		zephyr,resolution = <12>;
	};

	channel@b {  /* PA6 S3_AN2_ADC */
		reg = <11>;
		zephyr,gain = "ADC_GAIN_1";
		zephyr,reference = "ADC_REF_INTERNAL";
		zephyr,acquisition-time = <ADC_ACQ_TIME(ADC_ACQ_TIME_TICKS, 815)>;
		zephyr,resolution = <12>;
	};

	channel@f {  /* PD11 S5_AN1_ADC */
		reg = <15>;
		zephyr,gain = "ADC_GAIN_1";
		zephyr,reference = "ADC_REF_INTERNAL";
		zephyr,acquisition-time = <ADC_ACQ_TIME(ADC_ACQ_TIME_TICKS, 815)>;
		zephyr,resolution = <12>;
	};

	channel@10 {  /* PD12 S5_AN2_ADC */
		reg = <16>;
		zephyr,gain = "ADC_GAIN_1";
		zephyr,reference = "ADC_REF_INTERNAL";
		zephyr,acquisition-time = <ADC_ACQ_TIME(ADC_ACQ_TIME_TICKS, 815)>;
		zephyr,resolution = <12>;
	};

	channel@11 {  /* PD13 S5_AN3_ADC */
		reg = <17>;
		zephyr,gain = "ADC_GAIN_1";
		zephyr,reference = "ADC_REF_INTERNAL";
		zephyr,acquisition-time = <ADC_ACQ_TIME(ADC_ACQ_TIME_TICKS, 815)>;
		zephyr,resolution = <12>;
	};

	channel@12 {  /* PB0 S4_AN2_ADC */
		reg = <18>;
		zephyr,gain = "ADC_GAIN_1";
		zephyr,reference = "ADC_REF_INTERNAL";
		zephyr,acquisition-time = <ADC_ACQ_TIME(ADC_ACQ_TIME_TICKS, 815)>;
		zephyr,resolution = <12>;
	};

	channel@13 {  /* PB1 S4_AN3_ADC */
		reg = <19>;
		zephyr,gain = "ADC_GAIN_1";
		zephyr,reference = "ADC_REF_INTERNAL";
		zephyr,acquisition-time = <ADC_ACQ_TIME(ADC_ACQ_TIME_TICKS, 815)>;
		zephyr,resolution = <12>;
	};

	channel@14 {  /* PA7 S3_AN3_ADC */
		reg = <20>;
		zephyr,gain = "ADC_GAIN_1";
		zephyr,reference = "ADC_REF_INTERNAL";
		zephyr,acquisition-time = <ADC_ACQ_TIME(ADC_ACQ_TIME_TICKS, 815)>;
		zephyr,resolution = <12>;
	};

	channel@16 {  /* PC4 S4_AN0_ADC */
		reg = <22>;
		zephyr,gain = "ADC_GAIN_1";
		zephyr,reference = "ADC_REF_INTERNAL";
		zephyr,acquisition-time = <ADC_ACQ_TIME(ADC_ACQ_TIME_TICKS, 815)>;
		zephyr,resolution = <12>;
	};

	channel@17 {  /* PC5 S4_AN1_ADC */
		reg = <23>;
		zephyr,gain = "ADC_GAIN_1";
		zephyr,reference = "ADC_REF_INTERNAL";
		zephyr,acquisition-time = <ADC_ACQ_TIME(ADC_ACQ_TIME_TICKS, 815)>;
		zephyr,resolution = <12>;
	};
};

/* VDDA from VREFINT (ADC1 IN0) and the die temperature (ADC1 IN19), for the lane sanity check. */
&vref1 {
	status = "okay";
};

&die_temp {
	status = "okay";
};
